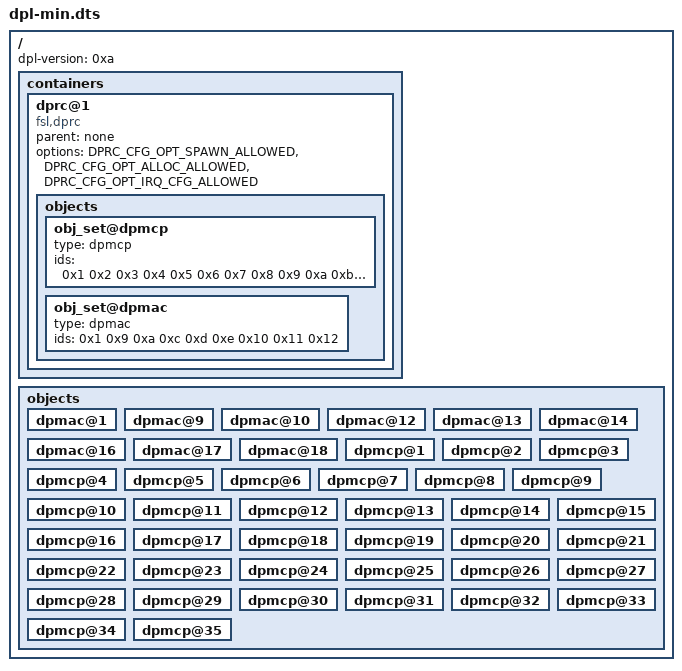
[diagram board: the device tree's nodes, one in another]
/* SPDX-License-Identifier: BSD-3-Clause */
/*
 * Copyright (c) 2021 TQ-Systems GmbH <oss@ew.tq-group.com>
 * D-82229 Seefeld, Germany.
 * Author: Gregor Herburger
 *
 * Copyright 2014-2016 Freescale Semiconductor, Inc.
 * Copyright 2017 NXP
 */

/dts-v1/;
/ {
	dpl-version = <0xa>;
	/*****************************************************************
	 * Containers
	 *****************************************************************/
	containers {
		dprc@1 {
			compatible = "fsl,dprc";
			parent = "none";
			options = "DPRC_CFG_OPT_SPAWN_ALLOWED" , "DPRC_CFG_OPT_ALLOC_ALLOWED", "DPRC_CFG_OPT_IRQ_CFG_ALLOWED";
			objects {
				/* ------------ DPMCPs --------------*/
				/* ------------ DPMCPs --------------*/
				obj_set@dpmcp {
					type = "dpmcp";
					ids = <0x1 0x2 0x3 0x4 0x5 0x6 0x7 0x8 0x9 0xa 0xb 0xc 0xd 0xe 0xf 0x10 0x11 0x12 0x13
					       0x14 0x15 0x16 0x17 0x18 0x19 0x1a 0x1b 0x1c 0x1d 0x1e 0x1f 0x20 0x21 0x22 0x23>;
				};

				obj_set@dpmac {
					type = "dpmac";
					ids = <0x1 0x9 0xa 0xc 0xd 0xe 0x10 0x11 0x12>;
				};
			};
		};
	};

	/*****************************************************************
	 * Objects
	 *****************************************************************/
	objects {
		/* ------------ DPMAC --------------*/
		dpmac@1 {
		};

		dpmac@9 {
		};

		dpmac@10 {
		};

		dpmac@12 {
		};

		dpmac@13 {
		};

		dpmac@14 {
		};

		dpmac@16 {
		};

		dpmac@17 {
		};

		dpmac@18 {
		};

		/* ------------ DPMCP --------------*/
		dpmcp@1 {
		};

		dpmcp@2 {
		};

		dpmcp@3 {
		};

		dpmcp@4 {
		};

		dpmcp@5 {
		};

		dpmcp@6 {
		};

		dpmcp@7 {
		};

		dpmcp@8 {
		};

		dpmcp@9 {
		};

		dpmcp@10 {
		};

		dpmcp@11 {
		};

		dpmcp@12 {
		};

		dpmcp@13 {
		};

		dpmcp@14 {
		};

		dpmcp@15 {
		};

		dpmcp@16 {
		};

		dpmcp@17 {
		};

		dpmcp@18 {
		};

		dpmcp@19 {
		};

		dpmcp@20 {
		};

		dpmcp@21 {
		};

		dpmcp@22 {
		};

		dpmcp@23 {
		};

		dpmcp@24 {
		};

		dpmcp@25 {
		};

		dpmcp@26 {
		};

		dpmcp@27 {
		};

		dpmcp@28 {
		};

		dpmcp@29 {
		};

		dpmcp@30 {
		};

		dpmcp@31 {
		};

		dpmcp@32 {
		};

		dpmcp@33 {
		};

		dpmcp@34 {
		};

		dpmcp@35 {
		};
	};
};
